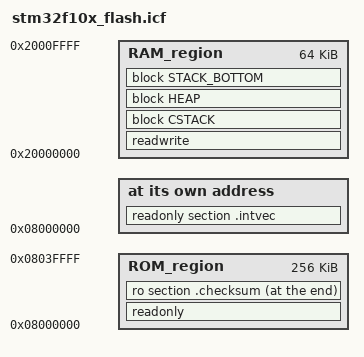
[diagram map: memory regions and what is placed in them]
/*###ICF### Section handled by ICF editor, don't touch! ****/
/*-Editor annotation file-*/
/* IcfEditorFile="$TOOLKIT_DIR$\config\ide\IcfEditor\cortex_v1_0.xml" */
/*-Specials-*/
define symbol __ICFEDIT_intvec_start__ = 0x08000000;
/*-Memory Regions-*/
define symbol __ICFEDIT_region_ROM_start__ = 0x08000000;
define symbol __ICFEDIT_region_ROM_end__   = 0x0803FFFF;
define symbol __ICFEDIT_region_RAM_start__ = 0x20000000;
define symbol __ICFEDIT_region_RAM_end__   = 0x2000FFFF;
/*-Sizes-*/
define symbol __ICFEDIT_size_cstack__       = 0x800;
define symbol __ICFEDIT_size_heap__         = 0x400;
define symbol __ICFEDIT_size_stack_bottom__ = 0x10;
/**** End of ICF editor section. ###ICF###*/

export symbol  __ICFEDIT_region_ROM_start__;
export symbol __ICFEDIT_region_ROM_end__;
export symbol __ICFEDIT_region_RAM_start__;
export symbol  __ICFEDIT_region_RAM_end__;
define memory mem with size = 4G;
define region ROM_region   = mem:[from __ICFEDIT_region_ROM_start__   to __ICFEDIT_region_ROM_end__];
define region RAM_region   = mem:[from __ICFEDIT_region_RAM_start__   to __ICFEDIT_region_RAM_end__];

define block CSTACK    with alignment = 8, size = __ICFEDIT_size_cstack__   { };
define block HEAP      with alignment = 8, size = __ICFEDIT_size_heap__     { };
define block STACK_BOTTOM  with alignment = 8, size = __ICFEDIT_size_stack_bottom__     { };

initialize by copy { readwrite };
do not initialize  { section .noinit, section  STACK_BOTTOM};

           

place at address mem:__ICFEDIT_intvec_start__ { readonly section .intvec };

place in ROM_region   { readonly };
place at end of ROM_region { ro section .checksum };
place in RAM_region   { readwrite };


place in RAM_region   {  block CSTACK, block HEAP,block STACK_BOTTOM, };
